# STM32G4xx register map
File version: 1.3
CPU: CM4 r0p1, little endian, MPU, FPU, 4 interrupt priority bits
Registers are 32-bit, read-write, reset 0x0 unless marked. A register's access mark holds for its fields unless they carry their own. Offsets are from the block's base; [hi:lo] are bit positions; {n}, {i} and the like mark numbered series.

## FPU — Floting point unit
Base 0xE000EF34
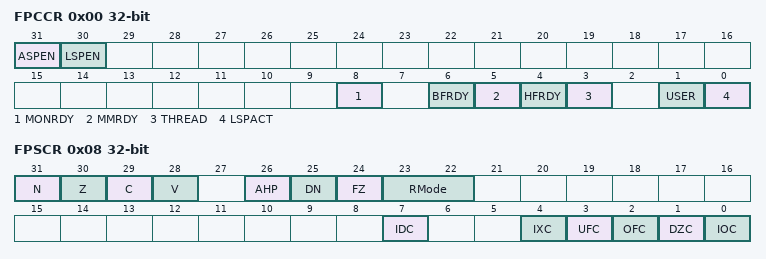
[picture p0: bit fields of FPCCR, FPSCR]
0x00 FPCCR — Floating-point context control register
  [31] ASPEN, [30] LSPEN, [8] MONRDY, [6] BFRDY, [5] MMRDY, [4] HFRDY, [3] THREAD, [1] USER, [0] LSPACT
0x04 FPCAR — Floating-point context address register
  [31:3] ADDRESS — Location of unpopulated floating-point
0x08 FPSCR — Floating-point status control register
  [31] N — Negative condition code flag
  [30] Z — Zero condition code flag
  [29] C — Carry condition code flag
  [28] V — Overflow condition code flag
  [26] AHP — Alternative half-precision control bit
  [25] DN — Default NaN mode control bit
  [24] FZ — Flush-to-zero mode control bit:
  [23:22] RMode — Rounding Mode control field
  [7] IDC — Input denormal cumulative exception bit.
  [4] IXC — Inexact cumulative exception bit
  [3] UFC — Underflow cumulative exception bit
  [2] OFC — Overflow cumulative exception bit
  [1] DZC — Division by zero cumulative exception bit.
  [0] IOC — Invalid operation cumulative exception bit

## MPU — Memory protection unit
Base 0xE000ED90
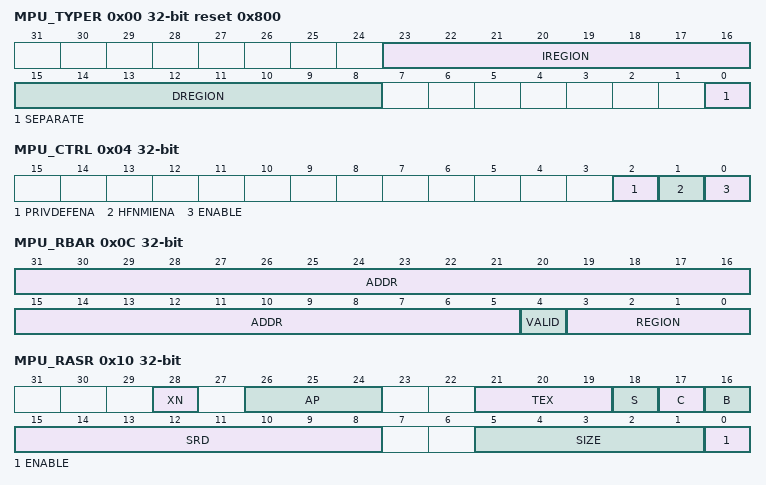
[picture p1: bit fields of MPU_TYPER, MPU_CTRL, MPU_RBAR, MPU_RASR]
0x00 MPU_TYPER ro reset 0x800 — MPU type register
  [23:16] IREGION — Number of MPU instruction regions
  [15:8] DREGION — Number of MPU data regions
  [0] SEPARATE — Separate flag
0x04 MPU_CTRL ro — MPU control register
  [2] PRIVDEFENA — Enable priviliged software access to default memory map
  [1] HFNMIENA — Enables the operation of MPU during hard fault
  [0] ENABLE — Enables the MPU
0x08 MPU_RNR — MPU region number register
  [7:0] REGION — MPU region
0x0C MPU_RBAR — MPU region base address register
  [31:5] ADDR — Region base address field
  [4] VALID — MPU region number valid
  [3:0] REGION — MPU region field
0x10 MPU_RASR — MPU region attribute and size register
  [28] XN — Instruction access disable bit
  [26:24] AP — Access permission
  [21:19] TEX — memory attribute
  [18] S — Shareable memory attribute
  [17] C — memory attribute
  [16] B — memory attribute
  [15:8] SRD — Subregion disable bits
  [5:1] SIZE — Size of the MPU protection region
  [0] ENABLE — Region enable bit.

## STK — SysTick timer
Base 0xE000E010
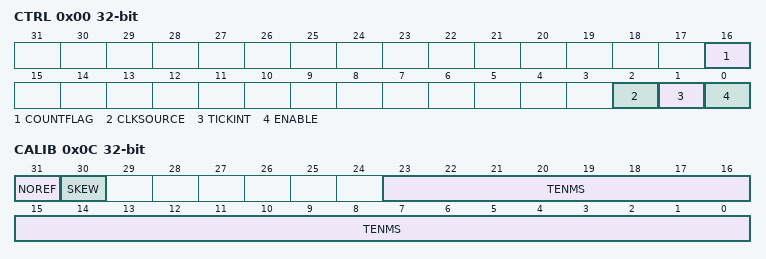
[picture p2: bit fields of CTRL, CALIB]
0x00 CTRL — SysTick control and status register
  [16] COUNTFLAG
  [2] CLKSOURCE — Clock source selection
  [1] TICKINT — SysTick exception request enable
  [0] ENABLE — Counter enable
0x04 LOAD — SysTick reload value register
  [23:0] RELOAD — RELOAD value
0x08 VAL — SysTick current value register
  [23:0] CURRENT — Current counter value
0x0C CALIB — SysTick calibration value register
  [31] NOREF — NOREF flag. Reads as zero
  [30] SKEW — SKEW flag: Indicates whether the TENMS value is exact
  [23:0] TENMS — Calibration value

## NVIC_STIR — Nested vectored interrupt controller
Base 0xE000EF00
0x00 STIR — Software trigger interrupt register
  [8:0] INTID — Software generated interrupt ID

## NVIC — Nested Vectored Interrupt Controller
Base 0xE000E100
{0x0+4i} ISER{i} (i=0..3) — Interrupt Set-Enable Register
  [31:0] SETENA
{0x80+4i} ICER{i} (i=0..3) — Interrupt Clear-Enable Register
  [31:0] CLRENA
{0x100+4i} ISPR{i} (i=0..3) — Interrupt Set-Pending Register
  [31:0] SETPEND
{0x180+4i} ICPR{i} (i=0..3) — Interrupt Clear-Pending Register
  [31:0] CLRPEND
{0x200+4i} IABR{i} ro (i=0..3) — Interrupt Active Bit Register
  [31:0] ACTIVE
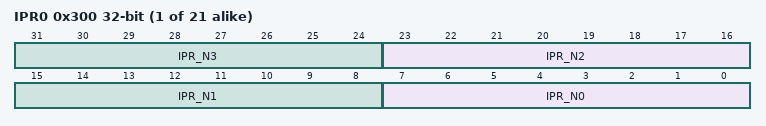
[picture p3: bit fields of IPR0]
{0x300+4i} IPR{i} (i=0..20) — Interrupt Priority Register
  [8n+7:8n] IPR_N{n} (n=0..3)
{0x300+4i} IPR{i} (i=21..25) — Interrupt Priority Register

## FPU_CPACR — Floating point unit CPACR
Base 0xE000ED88
0x00 CPACR — Coprocessor access control register
  [23:20] CP

## SCB_ACTRL — System control block ACTLR
Base 0xE000E008
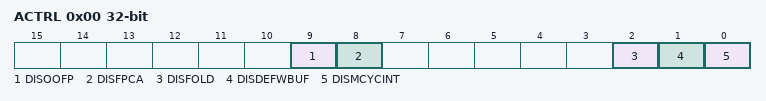
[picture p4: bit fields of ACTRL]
0x00 ACTRL — Auxiliary control register
  [9] DISOOFP, [8] DISFPCA, [2] DISFOLD, [1] DISDEFWBUF, [0] DISMCYCINT

## UCPD1
Base 0x4000A000
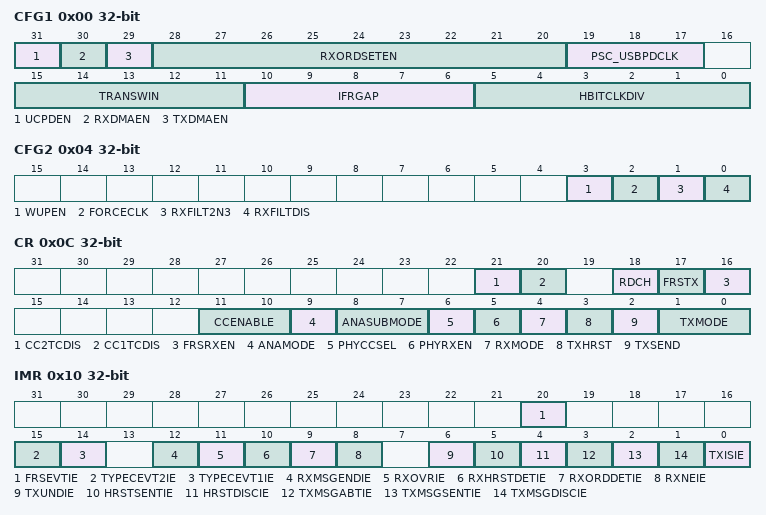
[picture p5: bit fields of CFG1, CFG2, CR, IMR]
0x00 CFG1 — UCPD configuration register 1
  [31] UCPDEN, [30] RXDMAEN, [29] TXDMAEN, [28:20] RXORDSETEN, [19:17] PSC_USBPDCLK, [15:11] TRANSWIN, [10:6] IFRGAP, [5:0] HBITCLKDIV
0x04 CFG2 — UCPD configuration register 2
  [3] WUPEN, [2] FORCECLK, [1] RXFILT2N3, [0] RXFILTDIS
0x0C CR — UCPD configuration register 2
  [21] CC2TCDIS, [20] CC1TCDIS, [18] RDCH, [17] FRSTX, [16] FRSRXEN, [11:10] CCENABLE, [9] ANAMODE, [8:7] ANASUBMODE, [6] PHYCCSEL, [5] PHYRXEN, [4] RXMODE, [3] TXHRST, [2] TXSEND, [1:0] TXMODE
0x10 IMR — UCPD Interrupt Mask Register
  [20] FRSEVTIE, [15] TYPECEVT2IE, [14] TYPECEVT1IE, [12] RXMSGENDIE, [11] RXOVRIE, [10] RXHRSTDETIE, [9] RXORDDETIE, [8] RXNEIE, [6] TXUNDIE, [5] HRSTSENTIE, [4] HRSTDISCIE, [3] TXMSGABTIE, [2] TXMSGSENTIE, [1] TXMSGDISCIE, [0] TXISIE
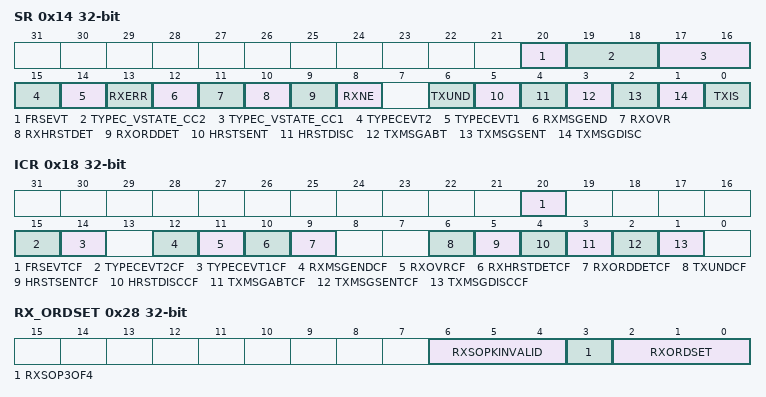
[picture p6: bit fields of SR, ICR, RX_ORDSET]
0x14 SR — UCPD Status Register
  [20] FRSEVT, [19:18] TYPEC_VSTATE_CC2, [17:16] TYPEC_VSTATE_CC1, [15] TYPECEVT2, [14] TYPECEVT1, [13] RXERR, [12] RXMSGEND, [11] RXOVR, [10] RXHRSTDET, [9] RXORDDET, [8] RXNE, [6] TXUND, [5] HRSTSENT, [4] HRSTDISC, [3] TXMSGABT, [2] TXMSGSENT, [1] TXMSGDISC, [0] TXIS
0x18 ICR — UCPD Interrupt Clear Register
  [20] FRSEVTCF, [15] TYPECEVT2CF, [14] TYPECEVT1CF, [12] RXMSGENDCF, [11] RXOVRCF, [10] RXHRSTDETCF, [9] RXORDDETCF, [6] TXUNDCF, [5] HRSTSENTCF, [4] HRSTDISCCF, [3] TXMSGABTCF, [2] TXMSGSENTCF, [1] TXMSGDISCCF
0x1C TX_ORDSET — UCPD Tx Ordered Set Type Register
  [19:0] TXORDSET
0x20 TX_PAYSZ — UCPD Tx Paysize Register
  [9:0] TXPAYSZ
0x24 TXDR — UCPD Tx Data Register
  [7:0] TXDATA
0x28 RX_ORDSET ro — UCPD Rx Ordered Set Register
  [6:4] RXSOPKINVALID, [3] RXSOP3OF4, [2:0] RXORDSET
0x2C RX_PAYSZ ro — UCPD Rx Paysize Register
  [9:0] RXPAYSZ
0x30 RXDR ro — UCPD Rx Data Register
  [7:0] RXDATA
0x34 RX_ORDEXT1 — UCPD Rx Ordered Set Extension Register 1
  [19:0] RXSOPX1
0x38 RX_ORDEXT2 — UCPD Rx Ordered Set Extension Register 2
  [19:0] RXSOPX2

## USB_FS_device
Base 0x40005C00
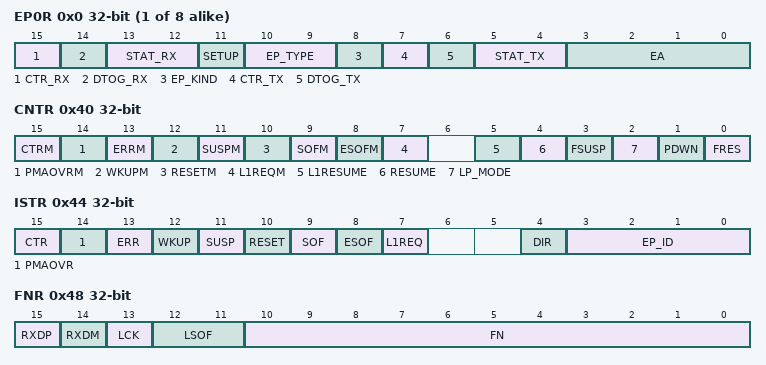
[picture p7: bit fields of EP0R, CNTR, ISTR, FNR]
{0x0+4i} EP{i}R (i=0..7) — USB endpoint n register
  [15] CTR_RX, [14] DTOG_RX, [13:12] STAT_RX, [11] SETUP, [10:9] EP_TYPE, [8] EP_KIND, [7] CTR_TX, [6] DTOG_TX, [5:4] STAT_TX, [3:0] EA
0x40 CNTR — USB control register
  [15] CTRM, [14] PMAOVRM, [13] ERRM, [12] WKUPM, [11] SUSPM, [10] RESETM, [9] SOFM, [8] ESOFM, [7] L1REQM, [5] L1RESUME, [4] RESUME, [3] FSUSP, [2] LP_MODE, [1] PDWN, [0] FRES
0x44 ISTR — USB interrupt status register
  [15] CTR, [14] PMAOVR, [13] ERR, [12] WKUP, [11] SUSP, [10] RESET, [9] SOF, [8] ESOF, [7] L1REQ, [4] DIR, [3:0] EP_ID
0x48 FNR ro — USB frame number register
  [15] RXDP, [14] RXDM, [13] LCK, [12:11] LSOF, [10:0] FN
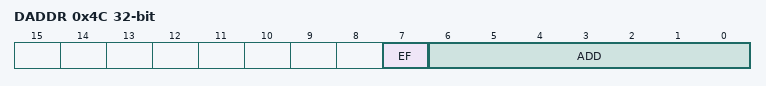
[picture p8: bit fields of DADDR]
0x4C DADDR — USB device address
  [7] EF, [6:0] ADD
0x50 BTABLE — Buffer table address
  [15:3] BTABLE
